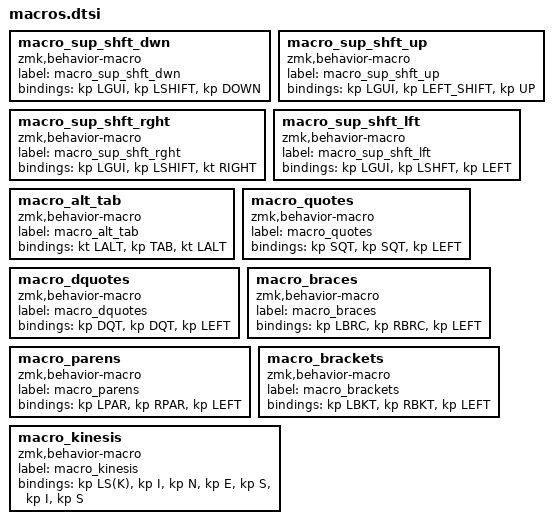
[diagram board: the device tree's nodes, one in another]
macro_sup_shft_dwn: macro_sup_shft_dwn{
compatible = "zmk,behavior-macro";
label = "macro_sup_shft_dwn";
#binding-cells = <0>;
bindings = <&kp LGUI>, <&kp LSHIFT>, <&kp DOWN>;
};
macro_sup_shft_up: macro_sup_shft_up{
compatible = "zmk,behavior-macro";
label = "macro_sup_shft_up";
#binding-cells = <0>;
bindings = <&kp LGUI>, <&kp LEFT_SHIFT>, <&kp UP>;
};
macro_sup_shft_rght: macro_sup_shft_rght{
compatible = "zmk,behavior-macro";
label = "macro_sup_shft_rght";
#binding-cells = <0>;
bindings = <&kp LGUI>, <&kp LSHIFT>, <&kt RIGHT>;
};
macro_sup_shft_lft: macro_sup_shft_lft{
compatible = "zmk,behavior-macro";
label = "macro_sup_shft_lft";
#binding-cells = <0>;
bindings = <&kp LGUI>, <&kp LSHFT>, <&kp LEFT>;
};
macro_alt_tab: macro_alt_tab{
compatible = "zmk,behavior-macro";
label = "macro_alt_tab";
#binding-cells = <0>;
bindings = <&kt LALT>, <&kp TAB>, <&kt LALT>;
};
macro_quotes: macro_quotes{
compatible = "zmk,behavior-macro";
label = "macro_quotes";
#binding-cells = <0>;
bindings = <&kp SQT>, <&kp SQT>, <&kp LEFT>;
};
macro_dquotes: macro_dquotes{
compatible = "zmk,behavior-macro";
label = "macro_dquotes";
#binding-cells = <0>;
bindings = <&kp DQT>, <&kp DQT>, <&kp LEFT>;
};
macro_braces: macro_braces{
compatible = "zmk,behavior-macro";
label = "macro_braces";
#binding-cells = <0>;
bindings = <&kp LBRC>, <&kp RBRC>, <&kp LEFT>;
};
macro_parens: macro_parens{
compatible = "zmk,behavior-macro";
label = "macro_parens";
#binding-cells = <0>;
bindings = <&kp LPAR>, <&kp RPAR>, <&kp LEFT>;
};
macro_brackets: macro_brackets{
compatible = "zmk,behavior-macro";
label = "macro_brackets";
#binding-cells = <0>;
bindings = <&kp LBKT>, <&kp RBKT>, <&kp LEFT>;
};
macro_kinesis: macro_kinesis{
compatible = "zmk,behavior-macro";
label = "macro_kinesis";
#binding-cells = <0>;
bindings = <&kp LS(K)>, <&kp I>, <&kp N>, <&kp E>, <&kp S>, <&kp I>, <&kp S>;
};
